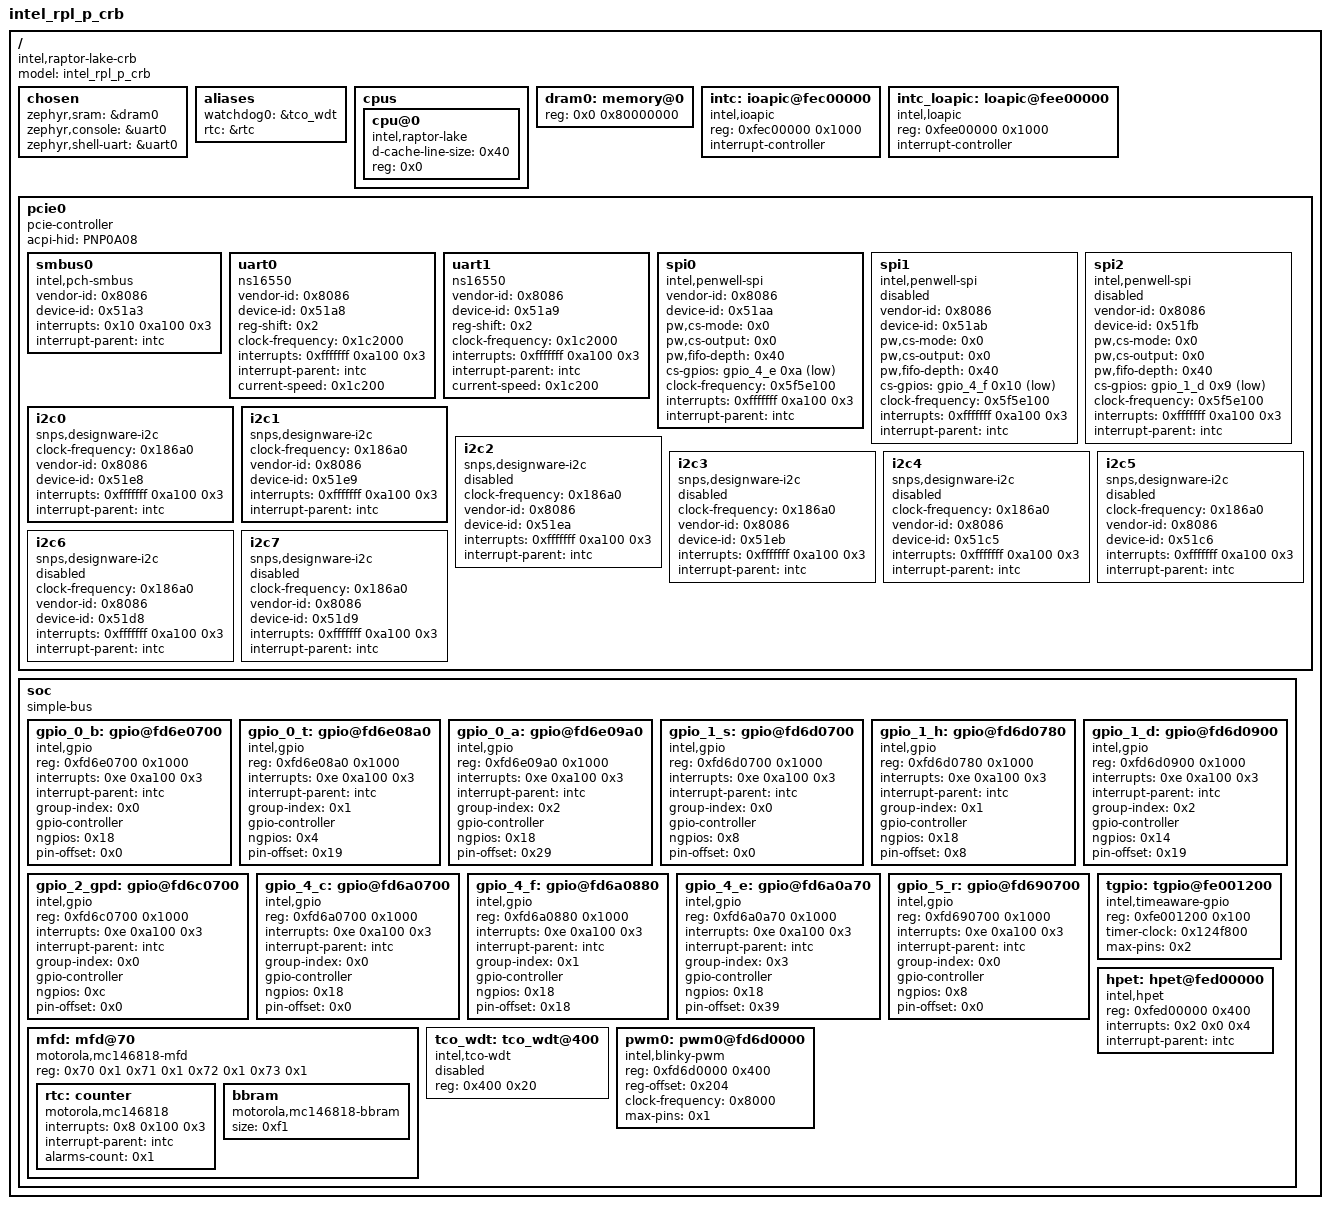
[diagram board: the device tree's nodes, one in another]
/dts-v1/;

/* node '/' defined in zephyr/dts/common/skeleton.dtsi:9 */
/ {
	#address-cells = < 0x1 >;             /* in zephyr/dts/common/skeleton.dtsi:10 */
	#size-cells = < 0x1 >;                /* in zephyr/dts/common/skeleton.dtsi:11 */
	model = "intel_rpl_p_crb";            /* in zephyr/boards/intel/rpl/intel_rpl_p_crb.dts:15 */
	compatible = "intel,raptor-lake-crb"; /* in zephyr/boards/intel/rpl/intel_rpl_p_crb.dts:16 */

	/* node '/chosen' defined in zephyr/dts/common/skeleton.dtsi:13 */
	chosen {
		zephyr,sram = &dram0;       /* in zephyr/boards/intel/rpl/intel_rpl_p_crb.dts:19 */
		zephyr,console = &uart0;    /* in zephyr/boards/intel/rpl/intel_rpl_p_crb.dts:20 */
		zephyr,shell-uart = &uart0; /* in zephyr/boards/intel/rpl/intel_rpl_p_crb.dts:21 */
	};

	/* node '/aliases' defined in zephyr/dts/common/skeleton.dtsi:15 */
	aliases {
		watchdog0 = &tco_wdt; /* in zephyr/boards/intel/rpl/intel_rpl_p_crb.dts:25 */
		rtc = &rtc;           /* in zephyr/boards/intel/rpl/intel_rpl_p_crb.dts:26 */
	};

	/* node '/cpus' defined in zephyr/dts/x86/intel/raptor_lake_p.dtsi:13 */
	cpus {
		#address-cells = < 0x1 >; /* in zephyr/dts/x86/intel/raptor_lake_p.dtsi:14 */
		#size-cells = < 0x0 >;    /* in zephyr/dts/x86/intel/raptor_lake_p.dtsi:15 */

		/* node '/cpus/cpu@0' defined in zephyr/dts/x86/intel/raptor_lake_p.dtsi:17 */
		cpu@0 {
			compatible = "intel,raptor-lake",
			             "intel,x86_64";      /* in zephyr/dts/x86/intel/raptor_lake_p.dtsi:18 */
			device_type = "cpu";              /* in zephyr/dts/x86/intel/raptor_lake_p.dtsi:19 */
			d-cache-line-size = < 0x40 >;     /* in zephyr/dts/x86/intel/raptor_lake_p.dtsi:20 */
			reg = < 0x0 >;                    /* in zephyr/dts/x86/intel/raptor_lake_p.dtsi:21 */
		};
	};

	/* node '/memory@0' defined in zephyr/dts/x86/intel/raptor_lake_p.dtsi:25 */
	dram0: memory@0 {
		device_type = "memory";   /* in zephyr/dts/x86/intel/raptor_lake_p.dtsi:26 */
		reg = < 0x0 0x80000000 >; /* in zephyr/dts/x86/intel/raptor_lake_p.dtsi:27 */
	};

	/* node '/ioapic@fec00000' defined in zephyr/dts/x86/intel/raptor_lake_p.dtsi:30 */
	intc: ioapic@fec00000 {
		compatible = "intel,ioapic"; /* in zephyr/dts/x86/intel/raptor_lake_p.dtsi:31 */
		reg = < 0xfec00000 0x1000 >; /* in zephyr/dts/x86/intel/raptor_lake_p.dtsi:32 */
		interrupt-controller;        /* in zephyr/dts/x86/intel/raptor_lake_p.dtsi:33 */
		#interrupt-cells = < 0x3 >;  /* in zephyr/dts/x86/intel/raptor_lake_p.dtsi:34 */
		phandle = < 0x1 >;           /* in zephyr/dts/x86/intel/raptor_lake_p.dtsi:59 */
	};

	/* node '/loapic@fee00000' defined in zephyr/dts/x86/intel/raptor_lake_p.dtsi:37 */
	intc_loapic: loapic@fee00000 {
		compatible = "intel,loapic"; /* in zephyr/dts/x86/intel/raptor_lake_p.dtsi:38 */
		reg = < 0xfee00000 0x1000 >; /* in zephyr/dts/x86/intel/raptor_lake_p.dtsi:39 */
		interrupt-controller;        /* in zephyr/dts/x86/intel/raptor_lake_p.dtsi:40 */
		#interrupt-cells = < 0x3 >;  /* in zephyr/dts/x86/intel/raptor_lake_p.dtsi:41 */
		#address-cells = < 0x1 >;    /* in zephyr/dts/x86/intel/raptor_lake_p.dtsi:42 */
	};

	/* node '/pcie0' defined in zephyr/dts/x86/intel/raptor_lake_p.dtsi:45 */
	pcie0: pcie0 {
		compatible = "pcie-controller"; /* in zephyr/dts/x86/intel/raptor_lake_p.dtsi:46 */
		#address-cells = < 0x1 >;       /* in zephyr/dts/x86/intel/raptor_lake_p.dtsi:47 */
		#size-cells = < 0x1 >;          /* in zephyr/dts/x86/intel/raptor_lake_p.dtsi:48 */
		acpi-hid = "PNP0A08";           /* in zephyr/dts/x86/intel/raptor_lake_p.dtsi:49 */
		ranges;                         /* in zephyr/dts/x86/intel/raptor_lake_p.dtsi:50 */

		/* node '/pcie0/smbus0' defined in zephyr/dts/x86/intel/raptor_lake_p.dtsi:52 */
		smbus0: smbus0 {
			compatible = "intel,pch-smbus";   /* in zephyr/dts/x86/intel/raptor_lake_p.dtsi:53 */
			#address-cells = < 0x1 >;         /* in zephyr/dts/x86/intel/raptor_lake_p.dtsi:54 */
			#size-cells = < 0x0 >;            /* in zephyr/dts/x86/intel/raptor_lake_p.dtsi:55 */
			vendor-id = < 0x8086 >;           /* in zephyr/dts/x86/intel/raptor_lake_p.dtsi:56 */
			device-id = < 0x51a3 >;           /* in zephyr/dts/x86/intel/raptor_lake_p.dtsi:57 */
			interrupts = < 0x10 0xa100 0x3 >; /* in zephyr/dts/x86/intel/raptor_lake_p.dtsi:58 */
			interrupt-parent = < &intc >;     /* in zephyr/dts/x86/intel/raptor_lake_p.dtsi:59 */
			status = "okay";                  /* in zephyr/dts/x86/intel/raptor_lake_p.dtsi:61 */
		};

		/* node '/pcie0/uart0' defined in zephyr/dts/x86/intel/raptor_lake_p.dtsi:64 */
		uart0: uart0 {
			compatible = "ns16550";                /* in zephyr/dts/x86/intel/raptor_lake_p.dtsi:65 */
			vendor-id = < 0x8086 >;                /* in zephyr/dts/x86/intel/raptor_lake_p.dtsi:66 */
			device-id = < 0x51a8 >;                /* in zephyr/dts/x86/intel/raptor_lake_p.dtsi:67 */
			reg-shift = < 0x2 >;                   /* in zephyr/dts/x86/intel/raptor_lake_p.dtsi:68 */
			clock-frequency = < 0x1c2000 >;        /* in zephyr/dts/x86/intel/raptor_lake_p.dtsi:69 */
			interrupts = < 0xfffffff 0xa100 0x3 >; /* in zephyr/dts/x86/intel/raptor_lake_p.dtsi:70 */
			interrupt-parent = < &intc >;          /* in zephyr/dts/x86/intel/raptor_lake_p.dtsi:71 */
			current-speed = < 0x1c200 >;           /* in zephyr/dts/x86/intel/raptor_lake_p.dtsi:72 */
			status = "okay";                       /* in zephyr/dts/x86/intel/raptor_lake_p.dtsi:74 */
		};

		/* node '/pcie0/uart1' defined in zephyr/dts/x86/intel/raptor_lake_p.dtsi:77 */
		uart1: uart1 {
			compatible = "ns16550";                /* in zephyr/dts/x86/intel/raptor_lake_p.dtsi:78 */
			vendor-id = < 0x8086 >;                /* in zephyr/dts/x86/intel/raptor_lake_p.dtsi:79 */
			device-id = < 0x51a9 >;                /* in zephyr/dts/x86/intel/raptor_lake_p.dtsi:80 */
			reg-shift = < 0x2 >;                   /* in zephyr/dts/x86/intel/raptor_lake_p.dtsi:81 */
			clock-frequency = < 0x1c2000 >;        /* in zephyr/dts/x86/intel/raptor_lake_p.dtsi:82 */
			interrupts = < 0xfffffff 0xa100 0x3 >; /* in zephyr/dts/x86/intel/raptor_lake_p.dtsi:83 */
			interrupt-parent = < &intc >;          /* in zephyr/dts/x86/intel/raptor_lake_p.dtsi:84 */
			current-speed = < 0x1c200 >;           /* in zephyr/dts/x86/intel/raptor_lake_p.dtsi:85 */
			status = "okay";                       /* in zephyr/dts/x86/intel/raptor_lake_p.dtsi:87 */
		};

		/* node '/pcie0/spi0' defined in zephyr/dts/x86/intel/raptor_lake_p.dtsi:90 */
		spi0: spi0 {
			compatible = "intel,penwell-spi";      /* in zephyr/dts/x86/intel/raptor_lake_p.dtsi:91 */
			#address-cells = < 0x1 >;              /* in zephyr/dts/x86/intel/raptor_lake_p.dtsi:92 */
			#size-cells = < 0x0 >;                 /* in zephyr/dts/x86/intel/raptor_lake_p.dtsi:93 */
			vendor-id = < 0x8086 >;                /* in zephyr/dts/x86/intel/raptor_lake_p.dtsi:94 */
			device-id = < 0x51aa >;                /* in zephyr/dts/x86/intel/raptor_lake_p.dtsi:95 */
			pw,cs-mode = < 0x0 >;                  /* in zephyr/dts/x86/intel/raptor_lake_p.dtsi:96 */
			pw,cs-output = < 0x0 >;                /* in zephyr/dts/x86/intel/raptor_lake_p.dtsi:97 */
			pw,fifo-depth = < 0x40 >;              /* in zephyr/dts/x86/intel/raptor_lake_p.dtsi:98 */
			cs-gpios = < &gpio_4_e 0xa 0x1 >;      /* in zephyr/dts/x86/intel/raptor_lake_p.dtsi:99 */
			clock-frequency = < 0x5f5e100 >;       /* in zephyr/dts/x86/intel/raptor_lake_p.dtsi:100 */
			interrupts = < 0xfffffff 0xa100 0x3 >; /* in zephyr/dts/x86/intel/raptor_lake_p.dtsi:101 */
			interrupt-parent = < &intc >;          /* in zephyr/dts/x86/intel/raptor_lake_p.dtsi:102 */
			status = "okay";                       /* in zephyr/dts/x86/intel/raptor_lake_p.dtsi:104 */
		};

		/* node '/pcie0/spi1' defined in zephyr/dts/x86/intel/raptor_lake_p.dtsi:107 */
		spi1: spi1 {
			compatible = "intel,penwell-spi";      /* in zephyr/dts/x86/intel/raptor_lake_p.dtsi:108 */
			#address-cells = < 0x1 >;              /* in zephyr/dts/x86/intel/raptor_lake_p.dtsi:109 */
			#size-cells = < 0x0 >;                 /* in zephyr/dts/x86/intel/raptor_lake_p.dtsi:110 */
			vendor-id = < 0x8086 >;                /* in zephyr/dts/x86/intel/raptor_lake_p.dtsi:111 */
			device-id = < 0x51ab >;                /* in zephyr/dts/x86/intel/raptor_lake_p.dtsi:112 */
			pw,cs-mode = < 0x0 >;                  /* in zephyr/dts/x86/intel/raptor_lake_p.dtsi:113 */
			pw,cs-output = < 0x0 >;                /* in zephyr/dts/x86/intel/raptor_lake_p.dtsi:114 */
			pw,fifo-depth = < 0x40 >;              /* in zephyr/dts/x86/intel/raptor_lake_p.dtsi:115 */
			cs-gpios = < &gpio_4_f 0x10 0x1 >;     /* in zephyr/dts/x86/intel/raptor_lake_p.dtsi:116 */
			clock-frequency = < 0x5f5e100 >;       /* in zephyr/dts/x86/intel/raptor_lake_p.dtsi:117 */
			interrupts = < 0xfffffff 0xa100 0x3 >; /* in zephyr/dts/x86/intel/raptor_lake_p.dtsi:118 */
			interrupt-parent = < &intc >;          /* in zephyr/dts/x86/intel/raptor_lake_p.dtsi:119 */
			status = "disabled";                   /* in zephyr/dts/x86/intel/raptor_lake_p.dtsi:121 */
		};

		/* node '/pcie0/spi2' defined in zephyr/dts/x86/intel/raptor_lake_p.dtsi:124 */
		spi2: spi2 {
			compatible = "intel,penwell-spi";      /* in zephyr/dts/x86/intel/raptor_lake_p.dtsi:125 */
			#address-cells = < 0x1 >;              /* in zephyr/dts/x86/intel/raptor_lake_p.dtsi:126 */
			#size-cells = < 0x0 >;                 /* in zephyr/dts/x86/intel/raptor_lake_p.dtsi:127 */
			vendor-id = < 0x8086 >;                /* in zephyr/dts/x86/intel/raptor_lake_p.dtsi:128 */
			device-id = < 0x51fb >;                /* in zephyr/dts/x86/intel/raptor_lake_p.dtsi:129 */
			pw,cs-mode = < 0x0 >;                  /* in zephyr/dts/x86/intel/raptor_lake_p.dtsi:130 */
			pw,cs-output = < 0x0 >;                /* in zephyr/dts/x86/intel/raptor_lake_p.dtsi:131 */
			pw,fifo-depth = < 0x40 >;              /* in zephyr/dts/x86/intel/raptor_lake_p.dtsi:132 */
			cs-gpios = < &gpio_1_d 0x9 0x1 >;      /* in zephyr/dts/x86/intel/raptor_lake_p.dtsi:133 */
			clock-frequency = < 0x5f5e100 >;       /* in zephyr/dts/x86/intel/raptor_lake_p.dtsi:134 */
			interrupts = < 0xfffffff 0xa100 0x3 >; /* in zephyr/dts/x86/intel/raptor_lake_p.dtsi:135 */
			interrupt-parent = < &intc >;          /* in zephyr/dts/x86/intel/raptor_lake_p.dtsi:136 */
			status = "disabled";                   /* in zephyr/dts/x86/intel/raptor_lake_p.dtsi:138 */
		};

		/* node '/pcie0/i2c0' defined in zephyr/dts/x86/intel/raptor_lake_p.dtsi:141 */
		i2c0: i2c0 {
			compatible = "snps,designware-i2c";    /* in zephyr/dts/x86/intel/raptor_lake_p.dtsi:142 */
			#address-cells = < 0x1 >;              /* in zephyr/dts/x86/intel/raptor_lake_p.dtsi:143 */
			#size-cells = < 0x0 >;                 /* in zephyr/dts/x86/intel/raptor_lake_p.dtsi:144 */
			clock-frequency = < 0x186a0 >;         /* in zephyr/dts/x86/intel/raptor_lake_p.dtsi:145 */
			vendor-id = < 0x8086 >;                /* in zephyr/dts/x86/intel/raptor_lake_p.dtsi:146 */
			device-id = < 0x51e8 >;                /* in zephyr/dts/x86/intel/raptor_lake_p.dtsi:147 */
			interrupts = < 0xfffffff 0xa100 0x3 >; /* in zephyr/dts/x86/intel/raptor_lake_p.dtsi:148 */
			interrupt-parent = < &intc >;          /* in zephyr/dts/x86/intel/raptor_lake_p.dtsi:149 */
			status = "okay";                       /* in zephyr/dts/x86/intel/raptor_lake_p.dtsi:151 */
		};

		/* node '/pcie0/i2c1' defined in zephyr/dts/x86/intel/raptor_lake_p.dtsi:154 */
		i2c1: i2c1 {
			compatible = "snps,designware-i2c";    /* in zephyr/dts/x86/intel/raptor_lake_p.dtsi:155 */
			#address-cells = < 0x1 >;              /* in zephyr/dts/x86/intel/raptor_lake_p.dtsi:156 */
			#size-cells = < 0x0 >;                 /* in zephyr/dts/x86/intel/raptor_lake_p.dtsi:157 */
			clock-frequency = < 0x186a0 >;         /* in zephyr/dts/x86/intel/raptor_lake_p.dtsi:158 */
			vendor-id = < 0x8086 >;                /* in zephyr/dts/x86/intel/raptor_lake_p.dtsi:159 */
			device-id = < 0x51e9 >;                /* in zephyr/dts/x86/intel/raptor_lake_p.dtsi:160 */
			interrupts = < 0xfffffff 0xa100 0x3 >; /* in zephyr/dts/x86/intel/raptor_lake_p.dtsi:161 */
			interrupt-parent = < &intc >;          /* in zephyr/dts/x86/intel/raptor_lake_p.dtsi:162 */
			status = "okay";                       /* in zephyr/dts/x86/intel/raptor_lake_p.dtsi:164 */
		};

		/* node '/pcie0/i2c2' defined in zephyr/dts/x86/intel/raptor_lake_p.dtsi:167 */
		i2c2: i2c2 {
			compatible = "snps,designware-i2c";    /* in zephyr/dts/x86/intel/raptor_lake_p.dtsi:168 */
			#address-cells = < 0x1 >;              /* in zephyr/dts/x86/intel/raptor_lake_p.dtsi:169 */
			#size-cells = < 0x0 >;                 /* in zephyr/dts/x86/intel/raptor_lake_p.dtsi:170 */
			clock-frequency = < 0x186a0 >;         /* in zephyr/dts/x86/intel/raptor_lake_p.dtsi:171 */
			vendor-id = < 0x8086 >;                /* in zephyr/dts/x86/intel/raptor_lake_p.dtsi:172 */
			device-id = < 0x51ea >;                /* in zephyr/dts/x86/intel/raptor_lake_p.dtsi:173 */
			interrupts = < 0xfffffff 0xa100 0x3 >; /* in zephyr/dts/x86/intel/raptor_lake_p.dtsi:174 */
			interrupt-parent = < &intc >;          /* in zephyr/dts/x86/intel/raptor_lake_p.dtsi:175 */
			status = "disabled";                   /* in zephyr/dts/x86/intel/raptor_lake_p.dtsi:177 */
		};

		/* node '/pcie0/i2c3' defined in zephyr/dts/x86/intel/raptor_lake_p.dtsi:180 */
		i2c3: i2c3 {
			compatible = "snps,designware-i2c";    /* in zephyr/dts/x86/intel/raptor_lake_p.dtsi:181 */
			#address-cells = < 0x1 >;              /* in zephyr/dts/x86/intel/raptor_lake_p.dtsi:182 */
			#size-cells = < 0x0 >;                 /* in zephyr/dts/x86/intel/raptor_lake_p.dtsi:183 */
			clock-frequency = < 0x186a0 >;         /* in zephyr/dts/x86/intel/raptor_lake_p.dtsi:184 */
			vendor-id = < 0x8086 >;                /* in zephyr/dts/x86/intel/raptor_lake_p.dtsi:185 */
			device-id = < 0x51eb >;                /* in zephyr/dts/x86/intel/raptor_lake_p.dtsi:186 */
			interrupts = < 0xfffffff 0xa100 0x3 >; /* in zephyr/dts/x86/intel/raptor_lake_p.dtsi:187 */
			interrupt-parent = < &intc >;          /* in zephyr/dts/x86/intel/raptor_lake_p.dtsi:188 */
			status = "disabled";                   /* in zephyr/dts/x86/intel/raptor_lake_p.dtsi:190 */
		};

		/* node '/pcie0/i2c4' defined in zephyr/dts/x86/intel/raptor_lake_p.dtsi:193 */
		i2c4: i2c4 {
			compatible = "snps,designware-i2c";    /* in zephyr/dts/x86/intel/raptor_lake_p.dtsi:194 */
			#address-cells = < 0x1 >;              /* in zephyr/dts/x86/intel/raptor_lake_p.dtsi:195 */
			#size-cells = < 0x0 >;                 /* in zephyr/dts/x86/intel/raptor_lake_p.dtsi:196 */
			clock-frequency = < 0x186a0 >;         /* in zephyr/dts/x86/intel/raptor_lake_p.dtsi:197 */
			vendor-id = < 0x8086 >;                /* in zephyr/dts/x86/intel/raptor_lake_p.dtsi:198 */
			device-id = < 0x51c5 >;                /* in zephyr/dts/x86/intel/raptor_lake_p.dtsi:199 */
			interrupts = < 0xfffffff 0xa100 0x3 >; /* in zephyr/dts/x86/intel/raptor_lake_p.dtsi:200 */
			interrupt-parent = < &intc >;          /* in zephyr/dts/x86/intel/raptor_lake_p.dtsi:201 */
			status = "disabled";                   /* in zephyr/dts/x86/intel/raptor_lake_p.dtsi:203 */
		};

		/* node '/pcie0/i2c5' defined in zephyr/dts/x86/intel/raptor_lake_p.dtsi:206 */
		i2c5: i2c5 {
			compatible = "snps,designware-i2c";    /* in zephyr/dts/x86/intel/raptor_lake_p.dtsi:207 */
			#address-cells = < 0x1 >;              /* in zephyr/dts/x86/intel/raptor_lake_p.dtsi:208 */
			#size-cells = < 0x0 >;                 /* in zephyr/dts/x86/intel/raptor_lake_p.dtsi:209 */
			clock-frequency = < 0x186a0 >;         /* in zephyr/dts/x86/intel/raptor_lake_p.dtsi:210 */
			vendor-id = < 0x8086 >;                /* in zephyr/dts/x86/intel/raptor_lake_p.dtsi:211 */
			device-id = < 0x51c6 >;                /* in zephyr/dts/x86/intel/raptor_lake_p.dtsi:212 */
			interrupts = < 0xfffffff 0xa100 0x3 >; /* in zephyr/dts/x86/intel/raptor_lake_p.dtsi:213 */
			interrupt-parent = < &intc >;          /* in zephyr/dts/x86/intel/raptor_lake_p.dtsi:214 */
			status = "disabled";                   /* in zephyr/dts/x86/intel/raptor_lake_p.dtsi:216 */
		};

		/* node '/pcie0/i2c6' defined in zephyr/dts/x86/intel/raptor_lake_p.dtsi:219 */
		i2c6: i2c6 {
			compatible = "snps,designware-i2c";    /* in zephyr/dts/x86/intel/raptor_lake_p.dtsi:220 */
			#address-cells = < 0x1 >;              /* in zephyr/dts/x86/intel/raptor_lake_p.dtsi:221 */
			#size-cells = < 0x0 >;                 /* in zephyr/dts/x86/intel/raptor_lake_p.dtsi:222 */
			clock-frequency = < 0x186a0 >;         /* in zephyr/dts/x86/intel/raptor_lake_p.dtsi:223 */
			vendor-id = < 0x8086 >;                /* in zephyr/dts/x86/intel/raptor_lake_p.dtsi:224 */
			device-id = < 0x51d8 >;                /* in zephyr/dts/x86/intel/raptor_lake_p.dtsi:225 */
			interrupts = < 0xfffffff 0xa100 0x3 >; /* in zephyr/dts/x86/intel/raptor_lake_p.dtsi:226 */
			interrupt-parent = < &intc >;          /* in zephyr/dts/x86/intel/raptor_lake_p.dtsi:227 */
			status = "disabled";                   /* in zephyr/dts/x86/intel/raptor_lake_p.dtsi:229 */
		};

		/* node '/pcie0/i2c7' defined in zephyr/dts/x86/intel/raptor_lake_p.dtsi:232 */
		i2c7: i2c7 {
			compatible = "snps,designware-i2c";    /* in zephyr/dts/x86/intel/raptor_lake_p.dtsi:233 */
			#address-cells = < 0x1 >;              /* in zephyr/dts/x86/intel/raptor_lake_p.dtsi:234 */
			#size-cells = < 0x0 >;                 /* in zephyr/dts/x86/intel/raptor_lake_p.dtsi:235 */
			clock-frequency = < 0x186a0 >;         /* in zephyr/dts/x86/intel/raptor_lake_p.dtsi:236 */
			vendor-id = < 0x8086 >;                /* in zephyr/dts/x86/intel/raptor_lake_p.dtsi:237 */
			device-id = < 0x51d9 >;                /* in zephyr/dts/x86/intel/raptor_lake_p.dtsi:238 */
			interrupts = < 0xfffffff 0xa100 0x3 >; /* in zephyr/dts/x86/intel/raptor_lake_p.dtsi:239 */
			interrupt-parent = < &intc >;          /* in zephyr/dts/x86/intel/raptor_lake_p.dtsi:240 */
			status = "disabled";                   /* in zephyr/dts/x86/intel/raptor_lake_p.dtsi:242 */
		};
	};

	/* node '/soc' defined in zephyr/dts/x86/intel/raptor_lake_p.dtsi:246 */
	soc {
		compatible = "simple-bus"; /* in zephyr/dts/x86/intel/raptor_lake_p.dtsi:247 */
		#address-cells = < 0x1 >;  /* in zephyr/dts/x86/intel/raptor_lake_p.dtsi:248 */
		#size-cells = < 0x1 >;     /* in zephyr/dts/x86/intel/raptor_lake_p.dtsi:249 */
		ranges;                    /* in zephyr/dts/x86/intel/raptor_lake_p.dtsi:250 */

		/* node '/soc/gpio@fd6e0700' defined in zephyr/dts/x86/intel/raptor_lake_p.dtsi:252 */
		gpio_0_b: gpio@fd6e0700 {
			compatible = "intel,gpio";       /* in zephyr/dts/x86/intel/raptor_lake_p.dtsi:253 */
			reg = < 0xfd6e0700 0x1000 >;     /* in zephyr/dts/x86/intel/raptor_lake_p.dtsi:254 */
			interrupts = < 0xe 0xa100 0x3 >; /* in zephyr/dts/x86/intel/raptor_lake_p.dtsi:255 */
			interrupt-parent = < &intc >;    /* in zephyr/dts/x86/intel/raptor_lake_p.dtsi:256 */
			group-index = < 0x0 >;           /* in zephyr/dts/x86/intel/raptor_lake_p.dtsi:258 */
			gpio-controller;                 /* in zephyr/dts/x86/intel/raptor_lake_p.dtsi:259 */
			#gpio-cells = < 0x2 >;           /* in zephyr/dts/x86/intel/raptor_lake_p.dtsi:260 */
			ngpios = < 0x18 >;               /* in zephyr/dts/x86/intel/raptor_lake_p.dtsi:262 */
			pin-offset = < 0x0 >;            /* in zephyr/dts/x86/intel/raptor_lake_p.dtsi:263 */
			status = "okay";                 /* in zephyr/dts/x86/intel/raptor_lake_p.dtsi:265 */
		};

		/* node '/soc/gpio@fd6e08a0' defined in zephyr/dts/x86/intel/raptor_lake_p.dtsi:268 */
		gpio_0_t: gpio@fd6e08a0 {
			compatible = "intel,gpio";       /* in zephyr/dts/x86/intel/raptor_lake_p.dtsi:269 */
			reg = < 0xfd6e08a0 0x1000 >;     /* in zephyr/dts/x86/intel/raptor_lake_p.dtsi:270 */
			interrupts = < 0xe 0xa100 0x3 >; /* in zephyr/dts/x86/intel/raptor_lake_p.dtsi:271 */
			interrupt-parent = < &intc >;    /* in zephyr/dts/x86/intel/raptor_lake_p.dtsi:272 */
			group-index = < 0x1 >;           /* in zephyr/dts/x86/intel/raptor_lake_p.dtsi:274 */
			gpio-controller;                 /* in zephyr/dts/x86/intel/raptor_lake_p.dtsi:275 */
			#gpio-cells = < 0x2 >;           /* in zephyr/dts/x86/intel/raptor_lake_p.dtsi:276 */
			ngpios = < 0x4 >;                /* in zephyr/dts/x86/intel/raptor_lake_p.dtsi:278 */
			pin-offset = < 0x19 >;           /* in zephyr/dts/x86/intel/raptor_lake_p.dtsi:279 */
			status = "okay";                 /* in zephyr/dts/x86/intel/raptor_lake_p.dtsi:281 */
		};

		/* node '/soc/gpio@fd6e09a0' defined in zephyr/dts/x86/intel/raptor_lake_p.dtsi:284 */
		gpio_0_a: gpio@fd6e09a0 {
			compatible = "intel,gpio";       /* in zephyr/dts/x86/intel/raptor_lake_p.dtsi:285 */
			reg = < 0xfd6e09a0 0x1000 >;     /* in zephyr/dts/x86/intel/raptor_lake_p.dtsi:286 */
			interrupts = < 0xe 0xa100 0x3 >; /* in zephyr/dts/x86/intel/raptor_lake_p.dtsi:287 */
			interrupt-parent = < &intc >;    /* in zephyr/dts/x86/intel/raptor_lake_p.dtsi:288 */
			group-index = < 0x2 >;           /* in zephyr/dts/x86/intel/raptor_lake_p.dtsi:290 */
			gpio-controller;                 /* in zephyr/dts/x86/intel/raptor_lake_p.dtsi:291 */
			#gpio-cells = < 0x2 >;           /* in zephyr/dts/x86/intel/raptor_lake_p.dtsi:292 */
			ngpios = < 0x18 >;               /* in zephyr/dts/x86/intel/raptor_lake_p.dtsi:294 */
			pin-offset = < 0x29 >;           /* in zephyr/dts/x86/intel/raptor_lake_p.dtsi:295 */
			status = "okay";                 /* in zephyr/dts/x86/intel/raptor_lake_p.dtsi:297 */
		};

		/* node '/soc/gpio@fd6d0700' defined in zephyr/dts/x86/intel/raptor_lake_p.dtsi:300 */
		gpio_1_s: gpio@fd6d0700 {
			compatible = "intel,gpio";       /* in zephyr/dts/x86/intel/raptor_lake_p.dtsi:301 */
			reg = < 0xfd6d0700 0x1000 >;     /* in zephyr/dts/x86/intel/raptor_lake_p.dtsi:302 */
			interrupts = < 0xe 0xa100 0x3 >; /* in zephyr/dts/x86/intel/raptor_lake_p.dtsi:303 */
			interrupt-parent = < &intc >;    /* in zephyr/dts/x86/intel/raptor_lake_p.dtsi:304 */
			group-index = < 0x0 >;           /* in zephyr/dts/x86/intel/raptor_lake_p.dtsi:306 */
			gpio-controller;                 /* in zephyr/dts/x86/intel/raptor_lake_p.dtsi:307 */
			#gpio-cells = < 0x2 >;           /* in zephyr/dts/x86/intel/raptor_lake_p.dtsi:308 */
			ngpios = < 0x8 >;                /* in zephyr/dts/x86/intel/raptor_lake_p.dtsi:310 */
			pin-offset = < 0x0 >;            /* in zephyr/dts/x86/intel/raptor_lake_p.dtsi:311 */
			status = "okay";                 /* in zephyr/dts/x86/intel/raptor_lake_p.dtsi:313 */
		};

		/* node '/soc/gpio@fd6d0780' defined in zephyr/dts/x86/intel/raptor_lake_p.dtsi:316 */
		gpio_1_h: gpio@fd6d0780 {
			compatible = "intel,gpio";       /* in zephyr/dts/x86/intel/raptor_lake_p.dtsi:317 */
			reg = < 0xfd6d0780 0x1000 >;     /* in zephyr/dts/x86/intel/raptor_lake_p.dtsi:318 */
			interrupts = < 0xe 0xa100 0x3 >; /* in zephyr/dts/x86/intel/raptor_lake_p.dtsi:319 */
			interrupt-parent = < &intc >;    /* in zephyr/dts/x86/intel/raptor_lake_p.dtsi:320 */
			group-index = < 0x1 >;           /* in zephyr/dts/x86/intel/raptor_lake_p.dtsi:322 */
			gpio-controller;                 /* in zephyr/dts/x86/intel/raptor_lake_p.dtsi:323 */
			#gpio-cells = < 0x2 >;           /* in zephyr/dts/x86/intel/raptor_lake_p.dtsi:324 */
			ngpios = < 0x18 >;               /* in zephyr/dts/x86/intel/raptor_lake_p.dtsi:326 */
			pin-offset = < 0x8 >;            /* in zephyr/dts/x86/intel/raptor_lake_p.dtsi:327 */
			status = "okay";                 /* in zephyr/dts/x86/intel/raptor_lake_p.dtsi:329 */
		};

		/* node '/soc/gpio@fd6d0900' defined in zephyr/dts/x86/intel/raptor_lake_p.dtsi:332 */
		gpio_1_d: gpio@fd6d0900 {
			compatible = "intel,gpio";       /* in zephyr/dts/x86/intel/raptor_lake_p.dtsi:333 */
			reg = < 0xfd6d0900 0x1000 >;     /* in zephyr/dts/x86/intel/raptor_lake_p.dtsi:334 */
			interrupts = < 0xe 0xa100 0x3 >; /* in zephyr/dts/x86/intel/raptor_lake_p.dtsi:335 */
			interrupt-parent = < &intc >;    /* in zephyr/dts/x86/intel/raptor_lake_p.dtsi:336 */
			group-index = < 0x2 >;           /* in zephyr/dts/x86/intel/raptor_lake_p.dtsi:338 */
			gpio-controller;                 /* in zephyr/dts/x86/intel/raptor_lake_p.dtsi:339 */
			#gpio-cells = < 0x2 >;           /* in zephyr/dts/x86/intel/raptor_lake_p.dtsi:340 */
			ngpios = < 0x14 >;               /* in zephyr/dts/x86/intel/raptor_lake_p.dtsi:342 */
			pin-offset = < 0x19 >;           /* in zephyr/dts/x86/intel/raptor_lake_p.dtsi:343 */
			status = "okay";                 /* in zephyr/dts/x86/intel/raptor_lake_p.dtsi:345 */
			phandle = < 0x4 >;               /* in zephyr/dts/x86/intel/raptor_lake_p.dtsi:133 */
		};

		/* node '/soc/gpio@fd6c0700' defined in zephyr/dts/x86/intel/raptor_lake_p.dtsi:348 */
		gpio_2_gpd: gpio@fd6c0700 {
			compatible = "intel,gpio";       /* in zephyr/dts/x86/intel/raptor_lake_p.dtsi:349 */
			reg = < 0xfd6c0700 0x1000 >;     /* in zephyr/dts/x86/intel/raptor_lake_p.dtsi:350 */
			interrupts = < 0xe 0xa100 0x3 >; /* in zephyr/dts/x86/intel/raptor_lake_p.dtsi:351 */
			interrupt-parent = < &intc >;    /* in zephyr/dts/x86/intel/raptor_lake_p.dtsi:352 */
			group-index = < 0x0 >;           /* in zephyr/dts/x86/intel/raptor_lake_p.dtsi:354 */
			gpio-controller;                 /* in zephyr/dts/x86/intel/raptor_lake_p.dtsi:355 */
			#gpio-cells = < 0x2 >;           /* in zephyr/dts/x86/intel/raptor_lake_p.dtsi:356 */
			ngpios = < 0xc >;                /* in zephyr/dts/x86/intel/raptor_lake_p.dtsi:358 */
			pin-offset = < 0x0 >;            /* in zephyr/dts/x86/intel/raptor_lake_p.dtsi:359 */
			status = "okay";                 /* in zephyr/dts/x86/intel/raptor_lake_p.dtsi:361 */
		};

		/* node '/soc/gpio@fd6a0700' defined in zephyr/dts/x86/intel/raptor_lake_p.dtsi:364 */
		gpio_4_c: gpio@fd6a0700 {
			compatible = "intel,gpio";       /* in zephyr/dts/x86/intel/raptor_lake_p.dtsi:365 */
			reg = < 0xfd6a0700 0x1000 >;     /* in zephyr/dts/x86/intel/raptor_lake_p.dtsi:366 */
			interrupts = < 0xe 0xa100 0x3 >; /* in zephyr/dts/x86/intel/raptor_lake_p.dtsi:367 */
			interrupt-parent = < &intc >;    /* in zephyr/dts/x86/intel/raptor_lake_p.dtsi:368 */
			group-index = < 0x0 >;           /* in zephyr/dts/x86/intel/raptor_lake_p.dtsi:370 */
			gpio-controller;                 /* in zephyr/dts/x86/intel/raptor_lake_p.dtsi:371 */
			#gpio-cells = < 0x2 >;           /* in zephyr/dts/x86/intel/raptor_lake_p.dtsi:372 */
			ngpios = < 0x18 >;               /* in zephyr/dts/x86/intel/raptor_lake_p.dtsi:374 */
			pin-offset = < 0x0 >;            /* in zephyr/dts/x86/intel/raptor_lake_p.dtsi:375 */
			status = "okay";                 /* in zephyr/dts/x86/intel/raptor_lake_p.dtsi:377 */
		};

		/* node '/soc/gpio@fd6a0880' defined in zephyr/dts/x86/intel/raptor_lake_p.dtsi:380 */
		gpio_4_f: gpio@fd6a0880 {
			compatible = "intel,gpio";       /* in zephyr/dts/x86/intel/raptor_lake_p.dtsi:381 */
			reg = < 0xfd6a0880 0x1000 >;     /* in zephyr/dts/x86/intel/raptor_lake_p.dtsi:382 */
			interrupts = < 0xe 0xa100 0x3 >; /* in zephyr/dts/x86/intel/raptor_lake_p.dtsi:383 */
			interrupt-parent = < &intc >;    /* in zephyr/dts/x86/intel/raptor_lake_p.dtsi:384 */
			group-index = < 0x1 >;           /* in zephyr/dts/x86/intel/raptor_lake_p.dtsi:386 */
			gpio-controller;                 /* in zephyr/dts/x86/intel/raptor_lake_p.dtsi:387 */
			#gpio-cells = < 0x2 >;           /* in zephyr/dts/x86/intel/raptor_lake_p.dtsi:388 */
			ngpios = < 0x18 >;               /* in zephyr/dts/x86/intel/raptor_lake_p.dtsi:390 */
			pin-offset = < 0x18 >;           /* in zephyr/dts/x86/intel/raptor_lake_p.dtsi:391 */
			status = "okay";                 /* in zephyr/dts/x86/intel/raptor_lake_p.dtsi:393 */
			phandle = < 0x3 >;               /* in zephyr/dts/x86/intel/raptor_lake_p.dtsi:116 */
		};

		/* node '/soc/gpio@fd6a0a70' defined in zephyr/dts/x86/intel/raptor_lake_p.dtsi:396 */
		gpio_4_e: gpio@fd6a0a70 {
			compatible = "intel,gpio";       /* in zephyr/dts/x86/intel/raptor_lake_p.dtsi:397 */
			reg = < 0xfd6a0a70 0x1000 >;     /* in zephyr/dts/x86/intel/raptor_lake_p.dtsi:398 */
			interrupts = < 0xe 0xa100 0x3 >; /* in zephyr/dts/x86/intel/raptor_lake_p.dtsi:399 */
			interrupt-parent = < &intc >;    /* in zephyr/dts/x86/intel/raptor_lake_p.dtsi:400 */
			group-index = < 0x3 >;           /* in zephyr/dts/x86/intel/raptor_lake_p.dtsi:402 */
			gpio-controller;                 /* in zephyr/dts/x86/intel/raptor_lake_p.dtsi:403 */
			#gpio-cells = < 0x2 >;           /* in zephyr/dts/x86/intel/raptor_lake_p.dtsi:404 */
			ngpios = < 0x18 >;               /* in zephyr/dts/x86/intel/raptor_lake_p.dtsi:406 */
			pin-offset = < 0x39 >;           /* in zephyr/dts/x86/intel/raptor_lake_p.dtsi:407 */
			status = "okay";                 /* in zephyr/dts/x86/intel/raptor_lake_p.dtsi:409 */
			phandle = < 0x2 >;               /* in zephyr/dts/x86/intel/raptor_lake_p.dtsi:99 */
		};

		/* node '/soc/gpio@fd690700' defined in zephyr/dts/x86/intel/raptor_lake_p.dtsi:412 */
		gpio_5_r: gpio@fd690700 {
			compatible = "intel,gpio";       /* in zephyr/dts/x86/intel/raptor_lake_p.dtsi:413 */
			reg = < 0xfd690700 0x1000 >;     /* in zephyr/dts/x86/intel/raptor_lake_p.dtsi:414 */
			interrupts = < 0xe 0xa100 0x3 >; /* in zephyr/dts/x86/intel/raptor_lake_p.dtsi:415 */
			interrupt-parent = < &intc >;    /* in zephyr/dts/x86/intel/raptor_lake_p.dtsi:416 */
			group-index = < 0x0 >;           /* in zephyr/dts/x86/intel/raptor_lake_p.dtsi:418 */
			gpio-controller;                 /* in zephyr/dts/x86/intel/raptor_lake_p.dtsi:419 */
			#gpio-cells = < 0x2 >;           /* in zephyr/dts/x86/intel/raptor_lake_p.dtsi:420 */
			ngpios = < 0x8 >;                /* in zephyr/dts/x86/intel/raptor_lake_p.dtsi:422 */
			pin-offset = < 0x0 >;            /* in zephyr/dts/x86/intel/raptor_lake_p.dtsi:423 */
			status = "okay";                 /* in zephyr/dts/x86/intel/raptor_lake_p.dtsi:425 */
		};

		/* node '/soc/tgpio@fe001200' defined in zephyr/dts/x86/intel/raptor_lake_p.dtsi:428 */
		tgpio: tgpio@fe001200 {
			compatible = "intel,timeaware-gpio"; /* in zephyr/dts/x86/intel/raptor_lake_p.dtsi:429 */
			reg = < 0xfe001200 0x100 >;          /* in zephyr/dts/x86/intel/raptor_lake_p.dtsi:430 */
			timer-clock = < 0x124f800 >;         /* in zephyr/dts/x86/intel/raptor_lake_p.dtsi:431 */
			max-pins = < 0x2 >;                  /* in zephyr/dts/x86/intel/raptor_lake_p.dtsi:432 */
			status = "okay";                     /* in zephyr/dts/x86/intel/raptor_lake_p.dtsi:434 */
		};

		/* node '/soc/mfd@70' defined in zephyr/dts/x86/intel/raptor_lake_p.dtsi:437 */
		mfd: mfd@70 {
			compatible = "motorola,mc146818-mfd";          /* in zephyr/dts/x86/intel/raptor_lake_p.dtsi:438 */
			reg = < 0x70 0x1 0x71 0x1 0x72 0x1 0x73 0x1 >; /* in zephyr/dts/x86/intel/raptor_lake_p.dtsi:439 */
			status = "okay";                               /* in zephyr/dts/x86/intel/raptor_lake_p.dtsi:456 */

			/* node '/soc/mfd@70/rtc' defined in zephyr/dts/x86/intel/raptor_lake_p.dtsi:441 */
			rtc: counter: rtc {
				compatible = "motorola,mc146818"; /* in zephyr/dts/x86/intel/raptor_lake_p.dtsi:442 */
				interrupts = < 0x8 0x100 0x3 >;   /* in zephyr/dts/x86/intel/raptor_lake_p.dtsi:443 */
				interrupt-parent = < &intc >;     /* in zephyr/dts/x86/intel/raptor_lake_p.dtsi:444 */
				alarms-count = < 0x1 >;           /* in zephyr/dts/x86/intel/raptor_lake_p.dtsi:445 */
				status = "okay";                  /* in zephyr/dts/x86/intel/raptor_lake_p.dtsi:447 */
			};

			/* node '/soc/mfd@70/bbram' defined in zephyr/dts/x86/intel/raptor_lake_p.dtsi:450 */
			bbram: bbram {
				compatible = "motorola,mc146818-bbram"; /* in zephyr/dts/x86/intel/raptor_lake_p.dtsi:451 */
				size = < 0xf1 >;                        /* in zephyr/dts/x86/intel/raptor_lake_p.dtsi:452 */
				status = "okay";                        /* in zephyr/dts/x86/intel/raptor_lake_p.dtsi:453 */
			};
		};

		/* node '/soc/hpet@fed00000' defined in zephyr/dts/x86/intel/raptor_lake_p.dtsi:459 */
		hpet: hpet@fed00000 {
			compatible = "intel,hpet";    /* in zephyr/dts/x86/intel/raptor_lake_p.dtsi:460 */
			reg = < 0xfed00000 0x400 >;   /* in zephyr/dts/x86/intel/raptor_lake_p.dtsi:461 */
			interrupts = < 0x2 0x0 0x4 >; /* in zephyr/dts/x86/intel/raptor_lake_p.dtsi:462 */
			interrupt-parent = < &intc >; /* in zephyr/dts/x86/intel/raptor_lake_p.dtsi:463 */
			status = "okay";              /* in zephyr/dts/x86/intel/raptor_lake_p.dtsi:465 */
		};

		/* node '/soc/tco_wdt@400' defined in zephyr/dts/x86/intel/raptor_lake_p.dtsi:468 */
		tco_wdt: tco_wdt@400 {
			compatible = "intel,tco-wdt"; /* in zephyr/dts/x86/intel/raptor_lake_p.dtsi:469 */
			reg = < 0x400 0x20 >;         /* in zephyr/dts/x86/intel/raptor_lake_p.dtsi:470 */
			status = "disabled";          /* in zephyr/dts/x86/intel/raptor_lake_p.dtsi:472 */
		};

		/* node '/soc/pwm0@fd6d0000' defined in zephyr/dts/x86/intel/raptor_lake_p.dtsi:475 */
		pwm0: pwm0@fd6d0000 {
			compatible = "intel,blinky-pwm"; /* in zephyr/dts/x86/intel/raptor_lake_p.dtsi:476 */
			reg = < 0xfd6d0000 0x400 >;      /* in zephyr/dts/x86/intel/raptor_lake_p.dtsi:477 */
			reg-offset = < 0x204 >;          /* in zephyr/dts/x86/intel/raptor_lake_p.dtsi:478 */
			clock-frequency = < 0x8000 >;    /* in zephyr/dts/x86/intel/raptor_lake_p.dtsi:479 */
			max-pins = < 0x1 >;              /* in zephyr/dts/x86/intel/raptor_lake_p.dtsi:480 */
			#pwm-cells = < 0x2 >;            /* in zephyr/dts/x86/intel/raptor_lake_p.dtsi:481 */
			status = "okay";                 /* in zephyr/dts/x86/intel/raptor_lake_p.dtsi:483 */
		};
	};
};
